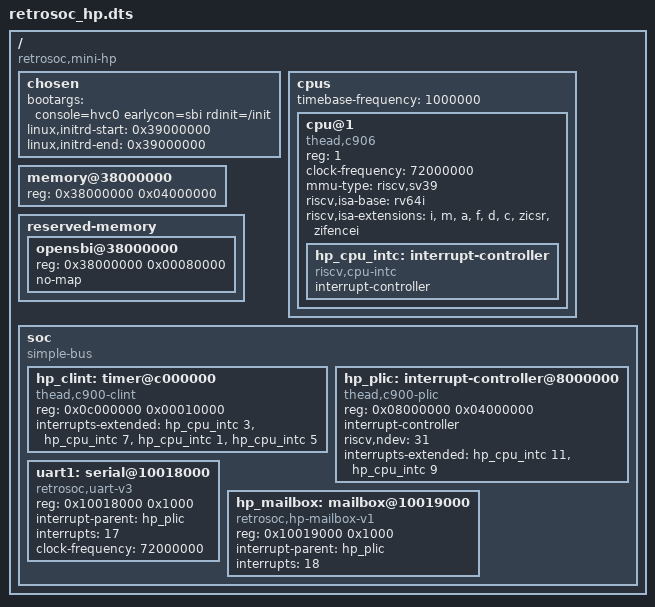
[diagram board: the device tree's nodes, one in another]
/dts-v1/;

/ {
	compatible = "retrosoc,mini-hp";
	#address-cells = <1>;
	#size-cells = <1>;

	chosen {
		bootargs = "console=hvc0 earlycon=sbi rdinit=/init";
		linux,initrd-start = <0x39000000>;
		/* build_hp_linux.py replaces this with the actual rootfs end. */
		linux,initrd-end = <0x39000000>;
	};

	cpus {
		#address-cells = <1>;
		#size-cells = <0>;
		timebase-frequency = <1000000>;

		cpu@1 {
			compatible = "thead,c906", "riscv";
			device_type = "cpu";
			reg = <1>;
			clock-frequency = <72000000>;
			mmu-type = "riscv,sv39";
			riscv,isa-base = "rv64i";
			riscv,isa-extensions = "i", "m", "a", "f", "d", "c",
					       "zicsr", "zifencei";

			hp_cpu_intc: interrupt-controller {
				compatible = "riscv,cpu-intc";
				interrupt-controller;
				#address-cells = <0>;
				#interrupt-cells = <1>;
			};
		};
	};

	memory@38000000 {
		device_type = "memory";
		reg = <0x38000000 0x04000000>;
	};

	reserved-memory {
		#address-cells = <1>;
		#size-cells = <1>;
		ranges;

		/* OpenSBI remains resident for every supervisor SBI call. */
		opensbi@38000000 {
			reg = <0x38000000 0x00080000>;
			no-map;
		};
	};

	soc {
		compatible = "simple-bus";
		#address-cells = <1>;
		#size-cells = <1>;
		ranges;

		/*
		 * Internal C906 CLINT (thead,c900-clint): decoded by the core
		 * BIU, not a SoC fabric slave. No memory-mapped mtime; software
		 * reads the time CSR. Interrupt order per hart: M-SW, M-timer,
		 * S-SW, S-timer.
		 */
		hp_clint: timer@c000000 {
			compatible = "thead,c900-clint";
			reg = <0x0c000000 0x00010000>;
			interrupts-extended = <&hp_cpu_intc 3>, <&hp_cpu_intc 7>,
					      <&hp_cpu_intc 1>, <&hp_cpu_intc 5>;
		};

		/*
		 * Internal C906 PLIC (thead,c900-plic): decoded by the core
		 * BIU. SoC external source n is PLIC ID n+16; IDs 0-15 are
		 * reserved/internal.
		 */
		hp_plic: interrupt-controller@8000000 {
			compatible = "thead,c900-plic";
			reg = <0x08000000 0x04000000>;
			interrupt-controller;
			#address-cells = <0>;
			#interrupt-cells = <1>;
			riscv,ndev = <31>;
			interrupts-extended = <&hp_cpu_intc 11>, <&hp_cpu_intc 9>;
		};

		uart1: serial@10018000 {
			compatible = "retrosoc,uart-v3";
			reg = <0x10018000 0x1000>;
			interrupt-parent = <&hp_plic>;
			interrupts = <17>;
			clock-frequency = <72000000>;
			status = "okay";
		};

		hp_mailbox: mailbox@10019000 {
			compatible = "retrosoc,hp-mailbox-v1";
			reg = <0x10019000 0x1000>;
			interrupt-parent = <&hp_plic>;
			interrupts = <18>;
			#mbox-cells = <1>;
		};
	};
};
